VERSION ""

NS_ :

BS_:

BU_: Gateway_Front Gateway_Rear BMS_Master GI_Left GI_Right Dashboard Telemetry INS Programming Charger

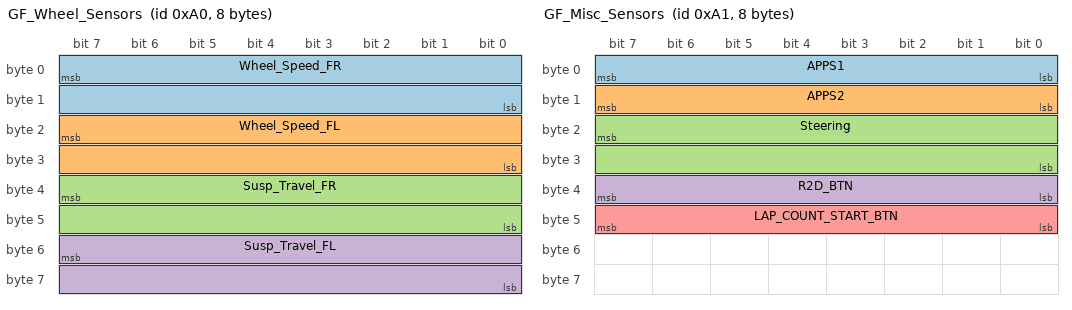
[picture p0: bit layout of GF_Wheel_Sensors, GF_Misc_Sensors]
BO_ 160 GF_Wheel_Sensors: 8 Gateway_Front
 SG_ Wheel_Speed_FR : 7|16@0+ (1.0, 0.0) [0.0|8000.0] "rpm" Telemetry,GI_Left,GI_Right,BMS_Master
 SG_ Wheel_Speed_FL : 23|16@0+ (1.0, 0.0) [0.0|8000.0] "rpm" Telemetry,GI_Left,GI_Right,BMS_Master
 SG_ Susp_Travel_FR : 39|16@0+ (0.001, 0.0) [0.0|65.535] "mm" Telemetry,GI_Left,GI_Right,BMS_Master
 SG_ Susp_Travel_FL : 55|16@0+ (0.001, 0.0) [0.0|65.535] "mm" Telemetry,GI_Left,GI_Right,BMS_Master

BO_ 161 GF_Misc_Sensors: 8 Gateway_Front
 SG_ APPS1 : 7|8@0+ (1.0, 0.0) [0.0|100.0] "%" Telemetry,GI_Left,GI_Right,BMS_Master
 SG_ APPS2 : 15|8@0+ (1.0, 0.0) [0.0|100.0] "%" Telemetry,GI_Left,GI_Right,BMS_Master
 SG_ Steering : 23|16@0- (0.01, 0.0) [-290.0|290.0] "deg" Telemetry,GI_Left,GI_Right,BMS_Master
 SG_ R2D_BTN : 39|8@0+ (1.0, 0.0) [0.0|1.0] "bool" Telemetry,GI_Left,GI_Right,BMS_Master
 SG_ LAP_COUNT_START_BTN : 47|8@0+ (1.0, 0.0) [0.0|1.0] "bool" Telemetry,GI_Left,GI_Right,BMS_Master

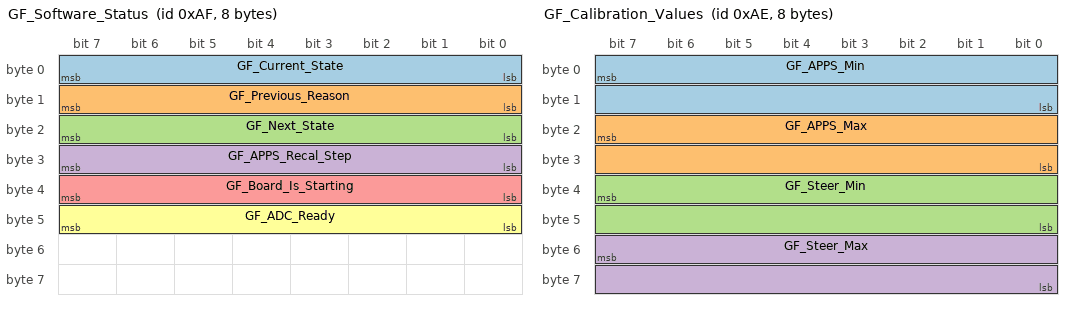
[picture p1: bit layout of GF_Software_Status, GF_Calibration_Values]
BO_ 175 GF_Software_Status: 8 Gateway_Front
 SG_ GF_Current_State : 7|8@0+ (1.0, 0.0) [0.0|255.0] "hex" Telemetry
 SG_ GF_Previous_Reason : 15|8@0+ (1.0, 0.0) [0.0|255.0] "hex" Telemetry
 SG_ GF_Next_State : 23|8@0+ (1.0, 0.0) [0.0|255.0] "hex" Telemetry
 SG_ GF_APPS_Recal_Step : 31|8@0+ (1.0, 0.0) [0.0|3.0] "hex" Telemetry
 SG_ GF_Board_Is_Starting : 39|8@0+ (1.0, 0.0) [0.0|1.0] "bool" Telemetry
 SG_ GF_ADC_Ready : 47|8@0+ (1.0, 0.0) [0.0|1.0] "bool" Telemetry

BO_ 174 GF_Calibration_Values: 8 Gateway_Front
 SG_ GF_APPS_Min : 7|16@0+ (1.0, 0.0) [0.0|65535.0] "dec" Telemetry,Dashboard
 SG_ GF_APPS_Max : 23|16@0+ (1.0, 0.0) [0.0|65535.0] "dec" Telemetry,Dashboard
 SG_ GF_Steer_Min : 39|16@0+ (1.0, 0.0) [0.0|65535.0] "dec" Telemetry,Dashboard
 SG_ GF_Steer_Max : 55|16@0+ (1.0, 0.0) [0.0|65535.0] "dec" Telemetry,Dashboard

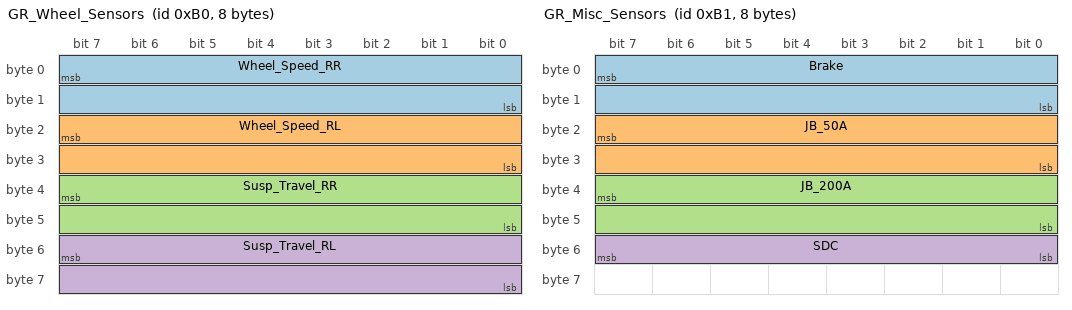
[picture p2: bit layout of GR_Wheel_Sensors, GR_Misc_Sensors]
BO_ 176 GR_Wheel_Sensors: 8 Gateway_Rear
 SG_ Wheel_Speed_RR : 7|16@0+ (1.0, 0.0) [0.0|8000.0] "rpm" Telemetry,GI_Left,GI_Right,BMS_Master
 SG_ Wheel_Speed_RL : 23|16@0+ (1.0, 0.0) [0.0|8000.0] "rpm" Telemetry,GI_Left,GI_Right,BMS_Master
 SG_ Susp_Travel_RR : 39|16@0+ (0.001, 0.0) [0.0|65.535] "mm" Telemetry,GI_Left,GI_Right,BMS_Master
 SG_ Susp_Travel_RL : 55|16@0+ (0.001, 0.0) [0.0|65.535] "mm" Telemetry,GI_Left,GI_Right,BMS_Master

BO_ 177 GR_Misc_Sensors: 8 Gateway_Rear
 SG_ Brake : 7|16@0+ (0.01, 0.0) [0.0|100.0] "bar" Telemetry,GI_Left,GI_Right,BMS_Master
 SG_ JB_50A : 23|16@0- (0.01, 0.0) [-70.0|70.0] "A" Telemetry,GI_Left,GI_Right,BMS_Master
 SG_ JB_200A : 39|16@0- (0.01, 0.0) [-300.0|300.0] "A" Telemetry,GI_Left,GI_Right,BMS_Master
 SG_ SDC : 55|8@0+ (1.0, 0.0) [0.0|1.0] "Bool" Telemetry,GI_Left,GI_Right,BMS_Master

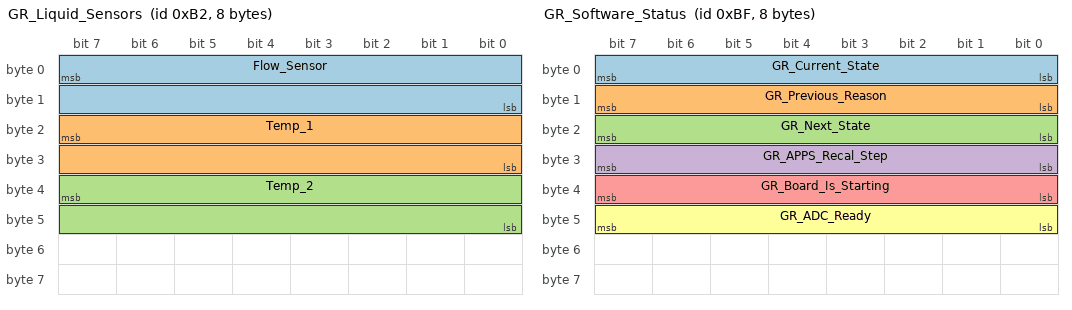
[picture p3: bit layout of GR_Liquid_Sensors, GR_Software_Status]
BO_ 178 GR_Liquid_Sensors: 8 Gateway_Rear
 SG_ Flow_Sensor : 7|16@0+ (1.0, 0.0) [0.0|100.0] "L/m" Telemetry
 SG_ Temp_1 : 23|16@0- (0.001, 0.0) [-10.0|100.0] "degC" Telemetry
 SG_ Temp_2 : 39|16@0- (0.001, 0.0) [-10.0|100.0] "degC" Telemetry

BO_ 191 GR_Software_Status: 8 Gateway_Rear
 SG_ GR_Current_State : 7|8@0+ (1.0, 0.0) [0.0|255.0] "hex" Telemetry
 SG_ GR_Previous_Reason : 15|8@0+ (1.0, 0.0) [0.0|255.0] "hex" Telemetry
 SG_ GR_Next_State : 23|8@0+ (1.0, 0.0) [0.0|255.0] "hex" Telemetry
 SG_ GR_APPS_Recal_Step : 31|8@0+ (1.0, 0.0) [0.0|3.0] "hex" Telemetry
 SG_ GR_Board_Is_Starting : 39|8@0+ (1.0, 0.0) [0.0|1.0] "bool" Telemetry
 SG_ GR_ADC_Ready : 47|8@0+ (1.0, 0.0) [0.0|1.0] "bool" Telemetry

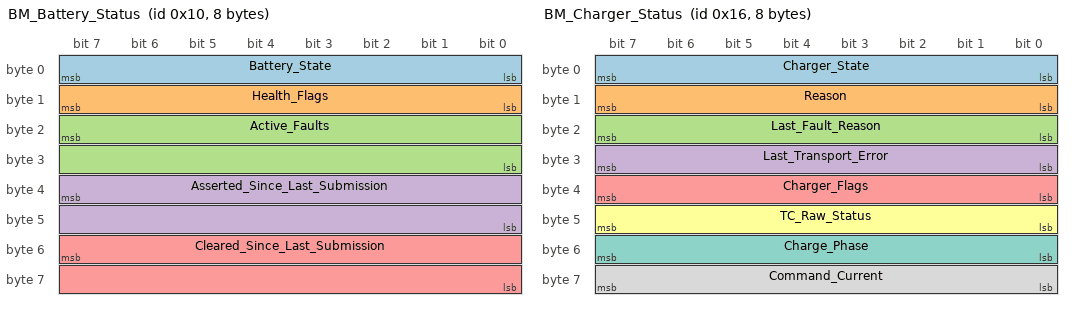
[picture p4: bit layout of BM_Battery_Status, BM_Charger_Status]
BO_ 16 BM_Battery_Status: 8 BMS_Master
 SG_ Battery_State : 7|8@0+ (1.0, 0.0) [0.0|5.0] "enum" Telemetry,Dashboard
 SG_ Health_Flags : 15|8@0+ (1.0, 0.0) [0.0|15.0] "bits" Telemetry,Dashboard
 SG_ Active_Faults : 23|16@0+ (1.0, 0.0) [0.0|32767.0] "bits" Telemetry,Dashboard
 SG_ Asserted_Since_Last_Submission : 39|16@0+ (1.0, 0.0) [0.0|32767.0] "bits" Telemetry,Dashboard
 SG_ Cleared_Since_Last_Submission : 55|16@0+ (1.0, 0.0) [0.0|32767.0] "bits" Telemetry,Dashboard

BO_ 22 BM_Charger_Status: 8 BMS_Master
 SG_ Charger_State : 7|8@0+ (1.0, 0.0) [0.0|5.0] "enum" Telemetry,Dashboard
 SG_ Reason : 15|8@0+ (1.0, 0.0) [0.0|9.0] "enum" Telemetry,Dashboard
 SG_ Last_Fault_Reason : 23|8@0+ (1.0, 0.0) [0.0|9.0] "enum" Telemetry,Dashboard
 SG_ Last_Transport_Error : 31|8@0+ (1.0, 0.0) [0.0|10.0] "enum" Telemetry,Dashboard
 SG_ Charger_Flags : 39|8@0+ (1.0, 0.0) [0.0|63.0] "bits" Telemetry,Dashboard
 SG_ TC_Raw_Status : 47|8@0+ (1.0, 0.0) [0.0|255.0] "bits" Telemetry,Dashboard
 SG_ Charge_Phase : 55|8@0+ (1.0, 0.0) [0.0|4.0] "enum" Telemetry,Dashboard
 SG_ Command_Current : 63|8@0+ (100.0, 0.0) [0.0|20000.0] "mA" Telemetry,Dashboard

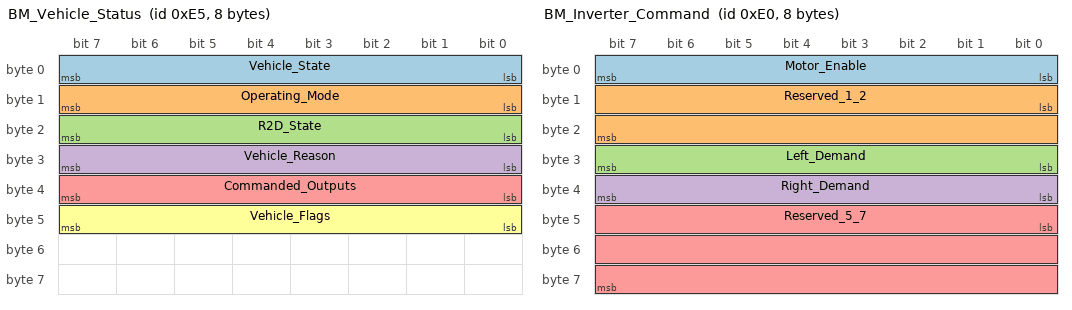
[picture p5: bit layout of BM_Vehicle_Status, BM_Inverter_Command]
BO_ 229 BM_Vehicle_Status: 8 BMS_Master
 SG_ Vehicle_State : 7|8@0+ (1.0, 0.0) [0.0|5.0] "enum" Telemetry,Dashboard
 SG_ Operating_Mode : 15|8@0+ (1.0, 0.0) [0.0|1.0] "enum" Telemetry,Dashboard
 SG_ R2D_State : 23|8@0+ (1.0, 0.0) [0.0|4.0] "enum" Telemetry,Dashboard
 SG_ Vehicle_Reason : 31|8@0+ (1.0, 0.0) [0.0|9.0] "enum" Telemetry,Dashboard
 SG_ Commanded_Outputs : 39|8@0+ (1.0, 0.0) [0.0|63.0] "bits" Telemetry,Dashboard
 SG_ Vehicle_Flags : 47|8@0+ (1.0, 0.0) [0.0|3.0] "bits" Telemetry,Dashboard

BO_ 224 BM_Inverter_Command: 8 BMS_Master
 SG_ Motor_Enable : 0|8@1+ (1.0, 0.0) [0.0|1.0] "bool" Telemetry,GI_Left,GI_Right
 SG_ Reserved_1_2 : 8|16@1+ (1.0, 0.0) [0.0|0.0] "" Telemetry,GI_Left,GI_Right
 SG_ Left_Demand : 24|8@1+ (1.0, 0.0) [0.0|100.0] "%" Telemetry,GI_Left,GI_Right
 SG_ Right_Demand : 32|8@1+ (1.0, 0.0) [0.0|100.0] "%" Telemetry,GI_Left,GI_Right
 SG_ Reserved_5_7 : 40|24@1+ (1.0, 0.0) [0.0|0.0] "" Telemetry,GI_Left,GI_Right

BO_ 179 BM_Rear_Buzzer: 8 BMS_Master
 SG_ R2D_Buzzer : 0|8@1+ (1.0, 0.0) [0.0|1.0] "bool" Telemetry,Gateway_Rear
 SG_ Reserved : 8|56@1+ (1.0, 0.0) [0.0|0.0] "" Telemetry,Gateway_Rear

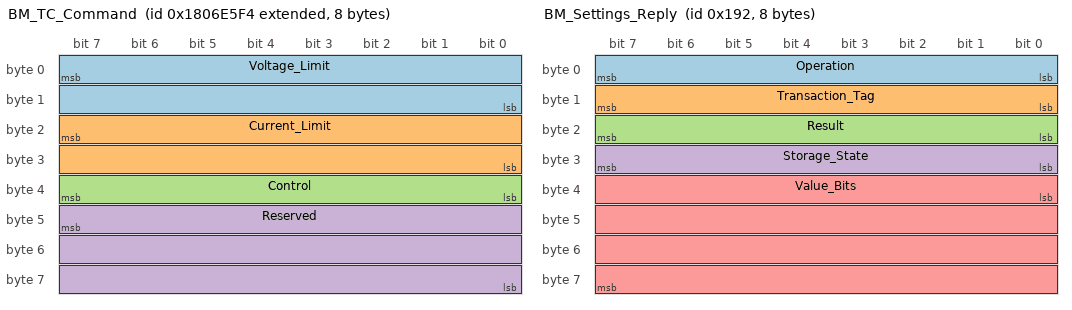
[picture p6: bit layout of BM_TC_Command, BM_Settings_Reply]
BO_ 2550588916 BM_TC_Command: 8 BMS_Master
 SG_ Voltage_Limit : 7|16@0+ (0.1, 0.0) [0.0|440.0] "V" Charger
 SG_ Current_Limit : 23|16@0+ (0.1, 0.0) [0.0|20.0] "A" Charger
 SG_ Control : 39|8@0+ (1.0, 0.0) [0.0|1.0] "enum" Charger
 SG_ Reserved : 47|24@0+ (1.0, 0.0) [0.0|0.0] "" Charger

BO_ 402 BM_Settings_Reply: 8 BMS_Master
 SG_ Operation : 0|8@1+ (1.0, 0.0) [0.0|255.0] "enum" Programming,Telemetry
 SG_ Transaction_Tag : 8|8@1+ (1.0, 0.0) [0.0|255.0] "" Programming,Telemetry
 SG_ Result : 16|8@1+ (1.0, 0.0) [0.0|10.0] "enum" Programming,Telemetry
 SG_ Storage_State : 24|8@1+ (1.0, 0.0) [0.0|3.0] "enum" Programming,Telemetry
 SG_ Value_Bits : 32|32@1+ (1.0, 0.0) [0.0|4294967295.0] "" Programming,Telemetry

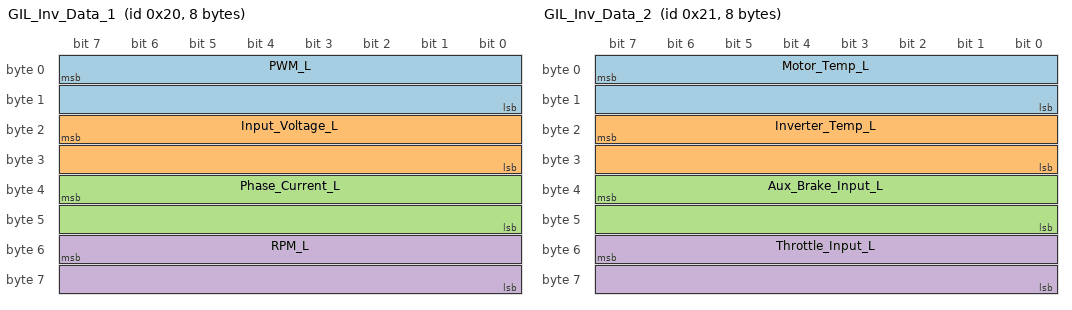
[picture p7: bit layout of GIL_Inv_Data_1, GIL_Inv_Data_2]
BO_ 32 GIL_Inv_Data_1: 8 GI_Left
 SG_ PWM_L : 7|16@0+ (1.0, 0.0) [0.0|1000.0] "raw" Telemetry
 SG_ Input_Voltage_L : 23|16@0+ (0.1, 0.0) [0.0|410.0] "V" Telemetry
 SG_ Phase_Current_L : 39|16@0+ (0.1, 0.0) [0.0|511.0] "A" Telemetry
 SG_ RPM_L : 55|16@0+ (1.0, 0.0) [0.0|65535.0] "rpm" Telemetry

BO_ 33 GIL_Inv_Data_2: 8 GI_Left
 SG_ Motor_Temp_L : 7|16@0- (1.0, 0.0) [-100.0|155.0] "degC" Telemetry
 SG_ Inverter_Temp_L : 23|16@0- (1.0, 0.0) [-100.0|155.0] "degC" Telemetry
 SG_ Aux_Brake_Input_L : 39|16@0+ (0.001, 0.0) [0.0|5.0] "V" Telemetry
 SG_ Throttle_Input_L : 55|16@0+ (0.001, 0.0) [0.0|5.0] "V" Telemetry

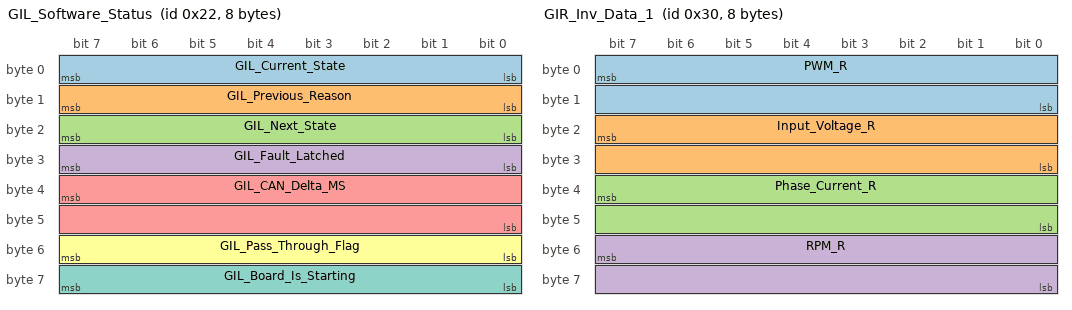
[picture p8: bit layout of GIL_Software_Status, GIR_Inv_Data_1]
BO_ 34 GIL_Software_Status: 8 GI_Left
 SG_ GIL_Current_State : 7|8@0+ (1.0, 0.0) [0.0|255.0] "hex" Telemetry
 SG_ GIL_Previous_Reason : 15|8@0+ (1.0, 0.0) [0.0|255.0] "hex" Telemetry
 SG_ GIL_Next_State : 23|8@0+ (1.0, 0.0) [0.0|255.0] "hex" Telemetry
 SG_ GIL_Fault_Latched : 31|8@0+ (1.0, 0.0) [0.0|1.0] "bool" Telemetry
 SG_ GIL_CAN_Delta_MS : 39|16@0+ (1.0, 0.0) [0.0|65535.0] "hex" Telemetry
 SG_ GIL_Pass_Through_Flag : 55|8@0+ (1.0, 0.0) [0.0|1.0] "bool" Telemetry
 SG_ GIL_Board_Is_Starting : 63|8@0+ (1.0, 0.0) [0.0|1.0] "bool" Telemetry

BO_ 48 GIR_Inv_Data_1: 8 GI_Right
 SG_ PWM_R : 7|16@0+ (1.0, 0.0) [0.0|1000.0] "raw" Telemetry
 SG_ Input_Voltage_R : 23|16@0+ (0.1, 0.0) [0.0|410.0] "V" Telemetry
 SG_ Phase_Current_R : 39|16@0+ (0.1, 0.0) [0.0|511.0] "A" Telemetry
 SG_ RPM_R : 55|16@0+ (1.0, 0.0) [0.0|65535.0] "rpm" Telemetry

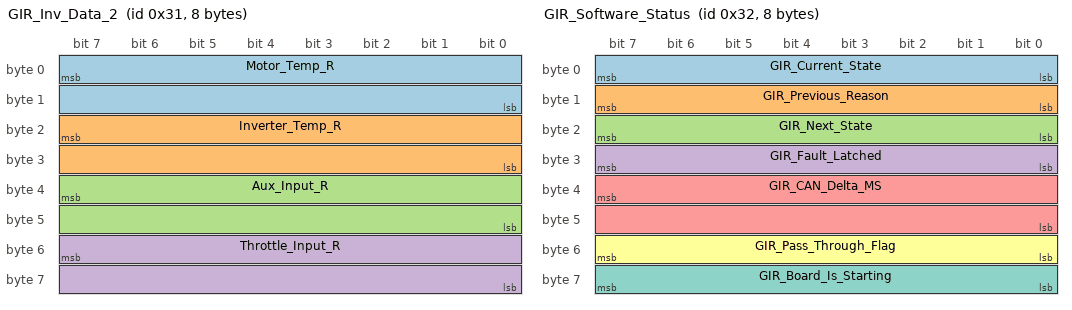
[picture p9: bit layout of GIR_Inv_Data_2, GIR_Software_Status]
BO_ 49 GIR_Inv_Data_2: 8 GI_Right
 SG_ Motor_Temp_R : 7|16@0- (1.0, 0.0) [-100.0|155.0] "degC" Telemetry
 SG_ Inverter_Temp_R : 23|16@0- (1.0, 0.0) [-100.0|155.0] "degC" Telemetry
 SG_ Aux_Input_R : 39|16@0+ (0.001, 0.0) [0.0|5.0] "V" Telemetry
 SG_ Throttle_Input_R : 55|16@0+ (0.001, 0.0) [0.0|5.0] "V" Telemetry

BO_ 50 GIR_Software_Status: 8 GI_Right
 SG_ GIR_Current_State : 7|8@0+ (1.0, 0.0) [0.0|255.0] "hex" Telemetry
 SG_ GIR_Previous_Reason : 15|8@0+ (1.0, 0.0) [0.0|255.0] "hex" Telemetry
 SG_ GIR_Next_State : 23|8@0+ (1.0, 0.0) [0.0|255.0] "hex" Telemetry
 SG_ GIR_Fault_Latched : 31|8@0+ (1.0, 0.0) [0.0|1.0] "bool" Telemetry
 SG_ GIR_CAN_Delta_MS : 39|16@0+ (1.0, 0.0) [0.0|65535.0] "hex" Telemetry
 SG_ GIR_Pass_Through_Flag : 55|8@0+ (1.0, 0.0) [0.0|1.0] "bool" Telemetry
 SG_ GIR_Board_Is_Starting : 63|8@0+ (1.0, 0.0) [0.0|1.0] "bool" Telemetry

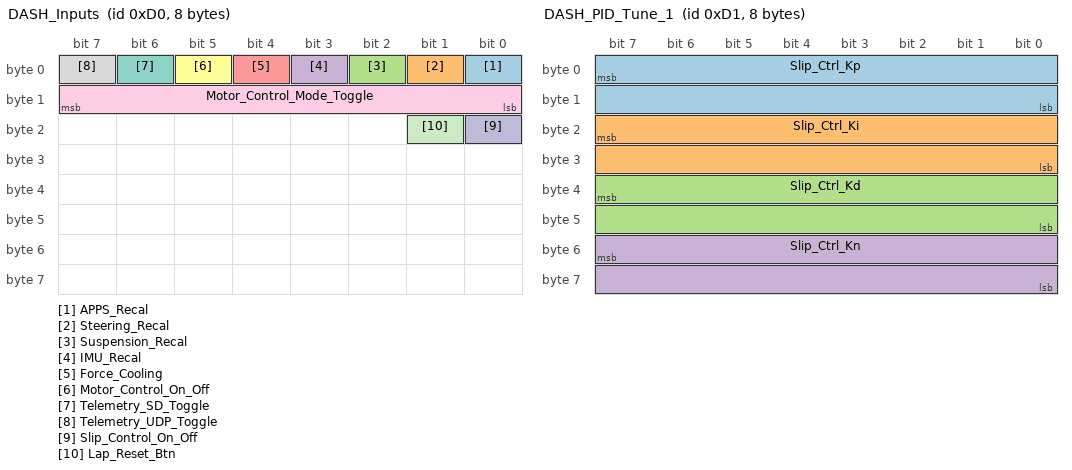
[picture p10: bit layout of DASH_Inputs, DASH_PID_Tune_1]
BO_ 208 DASH_Inputs: 8 Dashboard
 SG_ APPS_Recal : 0|1@1+ (1.0, 0.0) [0.0|1.0] "bool" Telemetry,BMS_Master
 SG_ Steering_Recal : 1|1@1+ (1.0, 0.0) [0.0|1.0] "bool" Telemetry,BMS_Master
 SG_ Suspension_Recal : 2|1@1+ (1.0, 0.0) [0.0|1.0] "bool" Telemetry,BMS_Master
 SG_ IMU_Recal : 3|1@1+ (1.0, 0.0) [0.0|1.0] "bool" Telemetry,BMS_Master
 SG_ Force_Cooling : 4|1@1+ (1.0, 0.0) [0.0|1.0] "bool" Telemetry,BMS_Master
 SG_ Motor_Control_On_Off : 5|1@1+ (1.0, 0.0) [0.0|1.0] "enum" Telemetry,BMS_Master
 SG_ Telemetry_SD_Toggle : 6|1@1+ (1.0, 0.0) [0.0|1.0] "bool" Telemetry,BMS_Master
 SG_ Telemetry_UDP_Toggle : 7|1@1+ (1.0, 0.0) [0.0|1.0] "bool" Telemetry,BMS_Master
 SG_ Motor_Control_Mode_Toggle : 15|8@0+ (1.0, 0.0) [0.0|255.0] "enum" Telemetry,BMS_Master
 SG_ Slip_Control_On_Off : 16|1@1+ (1.0, 0.0) [0.0|1.0] "bool" Telemetry,BMS_Master
 SG_ Lap_Reset_Btn : 17|1@1+ (1.0, 0.0) [0.0|1.0] "bool" Telemetry,BMS_Master

BO_ 209 DASH_PID_Tune_1: 8 Dashboard
 SG_ Slip_Ctrl_Kp : 7|16@0+ (1.0, 0.0) [0.0|65535.0] "unit" Telemetry
 SG_ Slip_Ctrl_Ki : 23|16@0+ (1.0, 0.0) [0.0|65535.0] "unit" Telemetry
 SG_ Slip_Ctrl_Kd : 39|16@0+ (0.01, 0.0) [0.0|655.35] "unit" Telemetry
 SG_ Slip_Ctrl_Kn : 55|16@0+ (1.0, 0.0) [0.0|100.0] "unit" Telemetry

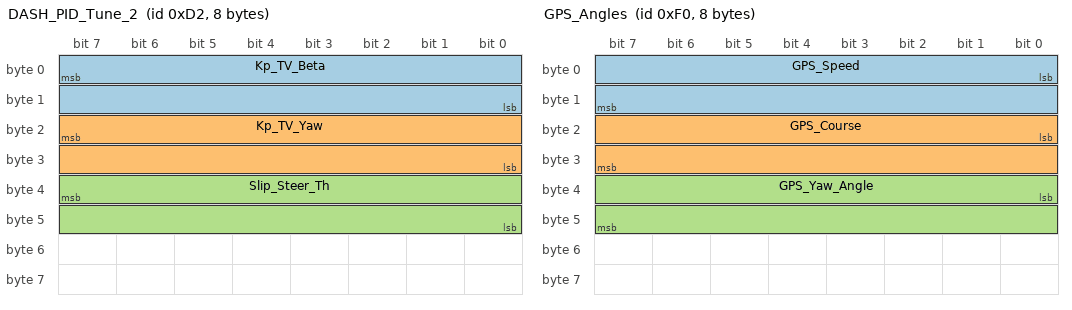
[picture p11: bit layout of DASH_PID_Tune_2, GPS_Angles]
BO_ 210 DASH_PID_Tune_2: 8 Dashboard
 SG_ Kp_TV_Beta : 7|16@0+ (1.0, 0.0) [0.0|1000.0] "unit" Telemetry
 SG_ Kp_TV_Yaw : 23|16@0+ (1.0, 0.0) [0.0|1500.0] "unit" Telemetry
 SG_ Slip_Steer_Th : 39|16@0+ (1.0, 0.0) [0.0|255.0] "deg" Telemetry

BO_ 240 GPS_Angles: 8 Telemetry
 SG_ GPS_Speed : 0|16@1- (0.01, 0.0) [0.0|327.67] "m/s" BMS_Master
 SG_ GPS_Course : 16|16@1- (0.0001, 0.0) [-3.15|3.15] "rad" BMS_Master
 SG_ GPS_Yaw_Angle : 32|16@1- (0.0001, 0.0) [-3.15|3.15] "rad" BMS_Master

BO_ 241 Lap_Completed: 8 Telemetry
 SG_ Lap_Completed_Flag : 7|8@0+ (1.0, 0.0) [0.0|1.0] "bool" Dashboard
 SG_ Lap_Count : 15|16@0+ (1.0, 0.0) [0.0|65535.0] "dec" Dashboard

BO_ 258 SBG_ECAN_MSG_STATUS_03: 6 INS
 SG_ SOLUTION : 0|32@1+ (1.0, 0.0) [0.0|4294967295.0] "" Telemetry
 SG_ HEAVE_STATUS : 32|16@1+ (1.0, 0.0) [0.0|65535.0] "" Telemetry

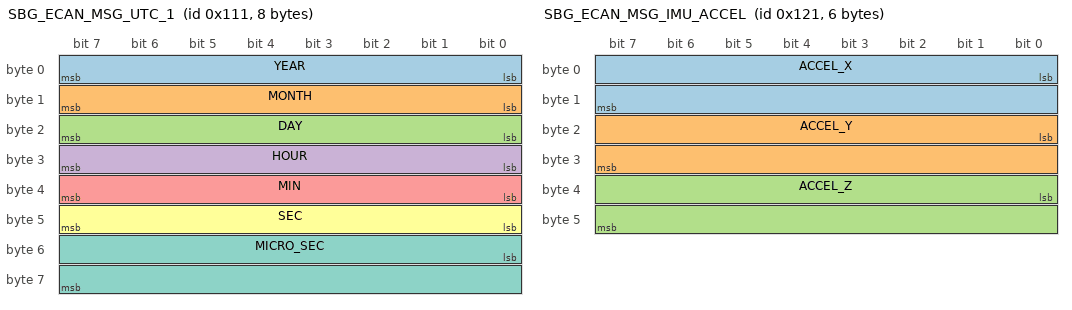
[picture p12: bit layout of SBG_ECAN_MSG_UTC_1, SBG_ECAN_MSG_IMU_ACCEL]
BO_ 273 SBG_ECAN_MSG_UTC_1: 8 INS
 SG_ YEAR : 0|8@1+ (1.0, 2000.0) [2000.0|2255.0] "year" Telemetry
 SG_ MONTH : 8|8@1+ (1.0, 0.0) [0.0|255.0] "month" Telemetry
 SG_ DAY : 16|8@1+ (1.0, 0.0) [0.0|255.0] "d" Telemetry
 SG_ HOUR : 24|8@1+ (1.0, 0.0) [0.0|255.0] "h" Telemetry
 SG_ MIN : 32|8@1+ (1.0, 0.0) [0.0|255.0] "min" Telemetry
 SG_ SEC : 40|8@1+ (1.0, 0.0) [0.0|255.0] "s" Telemetry
 SG_ MICRO_SEC : 48|16@1+ (100.0, 0.0) [0.0|6553500.0] "us" Telemetry

BO_ 289 SBG_ECAN_MSG_IMU_ACCEL: 6 INS
 SG_ ACCEL_X : 0|16@1- (0.01, 0.0) [-327.68|327.67] "m.s-2" BMS_Master,Telemetry
 SG_ ACCEL_Y : 16|16@1- (0.01, 0.0) [-327.68|327.67] "m.s-2" BMS_Master,Telemetry
 SG_ ACCEL_Z : 32|16@1- (0.01, 0.0) [-327.68|327.67] "m.s-2" BMS_Master,Telemetry

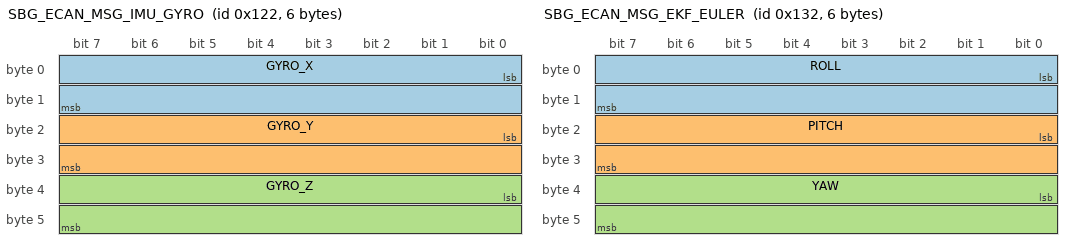
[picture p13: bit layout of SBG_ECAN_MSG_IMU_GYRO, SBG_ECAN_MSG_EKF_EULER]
BO_ 290 SBG_ECAN_MSG_IMU_GYRO: 6 INS
 SG_ GYRO_X : 0|16@1- (0.001, 0.0) [-32.768|32.767] "rad.s-1" BMS_Master,Telemetry
 SG_ GYRO_Y : 16|16@1- (0.001, 0.0) [-32.768|32.767] "rad.s-1" BMS_Master,Telemetry
 SG_ GYRO_Z : 32|16@1- (0.001, 0.0) [-32.768|32.767] "rad.s-1" BMS_Master,Telemetry

BO_ 306 SBG_ECAN_MSG_EKF_EULER: 6 INS
 SG_ ROLL : 0|16@1- (0.0001, 0.0) [-3.2768|3.2767] "rad" Telemetry
 SG_ PITCH : 16|16@1- (0.0001, 0.0) [-3.2768|3.2767] "rad" Telemetry
 SG_ YAW : 32|16@1- (0.0001, 0.0) [-3.2768|3.2767] "rad" Telemetry

BO_ 308 SBG_ECAN_MSG_EKF_POS: 8 INS
 SG_ LATITUDE : 0|32@1- (1e-07, 0.0) [-214.7483648|214.7483647] "Â°" Telemetry
 SG_ LONGITUDE : 32|32@1- (1e-07, 0.0) [-214.7483648|214.7483647] "Â°" Telemetry

BO_ 309 SBG_ECAN_MSG_EKF_ALTITUDE: 6 INS
 SG_ ALTITUDE : 0|32@1- (0.001, 0.0) [-2147480.0|2147480.0] "m" Telemetry
 SG_ UNDULATION : 32|16@1- (0.005, 0.0) [-163.84|163.835] "m" Telemetry

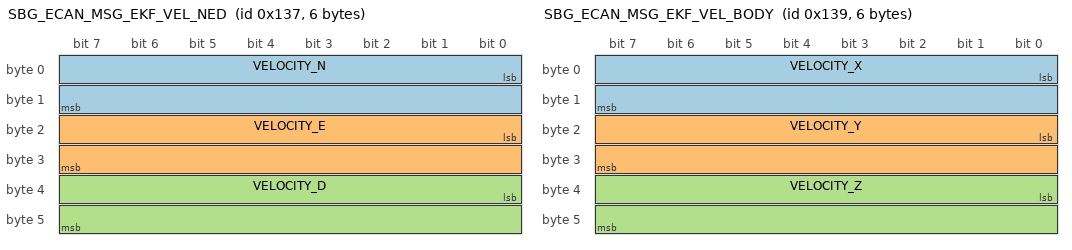
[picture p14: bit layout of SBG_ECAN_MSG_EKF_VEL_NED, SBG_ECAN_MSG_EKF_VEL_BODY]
BO_ 311 SBG_ECAN_MSG_EKF_VEL_NED: 6 INS
 SG_ VELOCITY_N : 0|16@1- (0.01, 0.0) [-327.68|327.67] "m.s-1" Telemetry
 SG_ VELOCITY_E : 16|16@1- (0.01, 0.0) [-327.68|327.67] "m.s-1" Telemetry
 SG_ VELOCITY_D : 32|16@1- (0.01, 0.0) [-327.68|327.67] "m.s-1" Telemetry

BO_ 313 SBG_ECAN_MSG_EKF_VEL_BODY: 6 INS
 SG_ VELOCITY_X : 0|16@1- (0.01, 0.0) [-327.68|327.67] "m.s-1" Telemetry
 SG_ VELOCITY_Y : 16|16@1- (0.01, 0.0) [-327.68|327.67] "m.s-1" Telemetry
 SG_ VELOCITY_Z : 32|16@1- (0.01, 0.0) [-327.68|327.67] "m.s-1" Telemetry

BO_ 372 SBG_ECAN_MSG_GPS1_POS_INFO: 8 INS
 SG_ TIME_STAMP : 0|32@1+ (1.0, 0.0) [0.0|4294967295.0] "Âµs" Telemetry
 SG_ STATUS : 32|32@1+ (1.0, 0.0) [0.0|4294967295.0] "" Telemetry

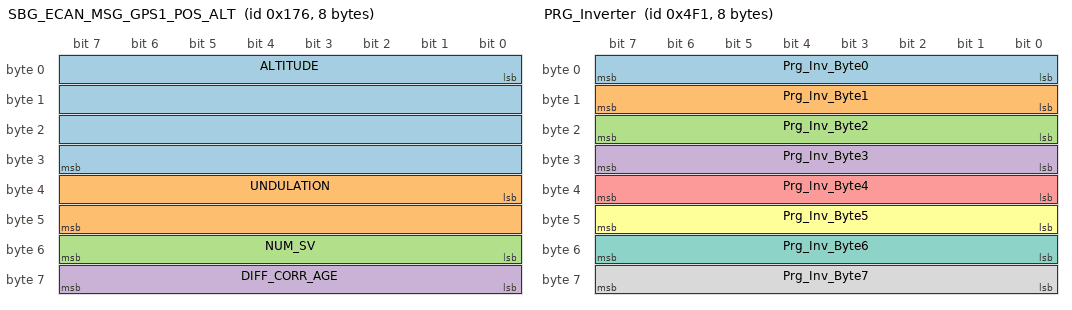
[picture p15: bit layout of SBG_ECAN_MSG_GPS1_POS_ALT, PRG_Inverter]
BO_ 374 SBG_ECAN_MSG_GPS1_POS_ALT: 8 INS
 SG_ ALTITUDE : 0|32@1- (0.001, 0.0) [-2147480.0|2147480.0] "m" Telemetry
 SG_ UNDULATION : 32|16@1- (0.005, 0.0) [-163.84|163.835] "m" Telemetry
 SG_ NUM_SV : 48|8@1+ (1.0, 0.0) [0.0|255.0] "" Telemetry
 SG_ DIFF_CORR_AGE : 56|8@1+ (1.0, 0.0) [0.0|255.0] "s" Telemetry

BO_ 1264 PRG_Bootloader: 8 Programming
 SG_ MCU_ID : 7|8@0+ (1.0, 0.0) [0.0|255.0] "id" Gateway_Front,Gateway_Rear,GI_Left,GI_Right,Dashboard,Telemetry

BO_ 1265 PRG_Inverter: 8 Programming
 SG_ Prg_Inv_Byte0 : 7|8@0+ (1.0, 0.0) [0.0|255.0] "hex" GI_Left,GI_Right
 SG_ Prg_Inv_Byte1 : 15|8@0+ (1.0, 0.0) [0.0|255.0] "hex" GI_Left,GI_Right
 SG_ Prg_Inv_Byte2 : 23|8@0+ (1.0, 0.0) [0.0|255.0] "hex" GI_Left,GI_Right
 SG_ Prg_Inv_Byte3 : 31|8@0+ (1.0, 0.0) [0.0|255.0] "hex" GI_Left,GI_Right
 SG_ Prg_Inv_Byte4 : 39|8@0+ (1.0, 0.0) [0.0|255.0] "hex" GI_Left,GI_Right
 SG_ Prg_Inv_Byte5 : 47|8@0+ (1.0, 0.0) [0.0|255.0] "hex" GI_Left,GI_Right
 SG_ Prg_Inv_Byte6 : 55|8@0+ (1.0, 0.0) [0.0|255.0] "hex" GI_Left,GI_Right
 SG_ Prg_Inv_Byte7 : 63|8@0+ (1.0, 0.0) [0.0|255.0] "hex" GI_Left,GI_Right

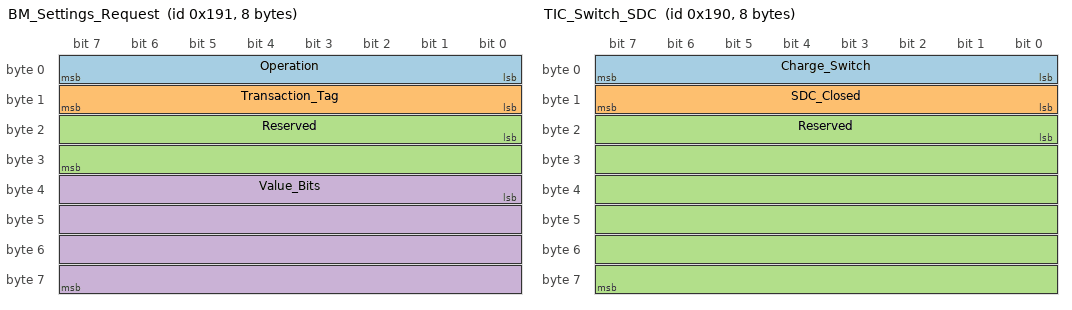
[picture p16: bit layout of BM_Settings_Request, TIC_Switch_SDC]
BO_ 401 BM_Settings_Request: 8 Programming
 SG_ Operation : 0|8@1+ (1.0, 0.0) [0.0|255.0] "enum" BMS_Master
 SG_ Transaction_Tag : 8|8@1+ (1.0, 0.0) [0.0|255.0] "" BMS_Master
 SG_ Reserved : 16|16@1+ (1.0, 0.0) [0.0|0.0] "" BMS_Master
 SG_ Value_Bits : 32|32@1+ (1.0, 0.0) [0.0|4294967295.0] "" BMS_Master

BO_ 400 TIC_Switch_SDC: 8 Charger
 SG_ Charge_Switch : 0|8@1+ (1.0, 0.0) [0.0|1.0] "bool" BMS_Master
 SG_ SDC_Closed : 8|8@1+ (1.0, 0.0) [0.0|1.0] "bool" BMS_Master
 SG_ Reserved : 16|48@1+ (1.0, 0.0) [0.0|0.0] "" BMS_Master

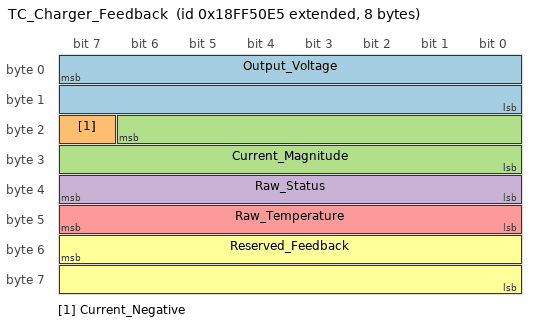
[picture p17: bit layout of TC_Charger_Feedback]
BO_ 2566869221 TC_Charger_Feedback: 8 Charger
 SG_ Output_Voltage : 7|16@0+ (0.1, 0.0) [0.0|6553.5] "V" BMS_Master
 SG_ Current_Negative : 23|1@0+ (1.0, 0.0) [0.0|1.0] "bool" BMS_Master
 SG_ Current_Magnitude : 22|15@0+ (0.1, 0.0) [0.0|3276.7] "A" BMS_Master
 SG_ Raw_Status : 39|8@0+ (1.0, 0.0) [0.0|255.0] "bits" BMS_Master
 SG_ Raw_Temperature : 47|8@0+ (1.0, 0.0) [0.0|255.0] "raw" BMS_Master
 SG_ Reserved_Feedback : 55|16@0+ (1.0, 0.0) [0.0|65535.0] "raw" BMS_Master

BA_DEF_ BO_ "GenMsgCycleTime" INT 0 65535;
BA_DEF_DEF_ "GenMsgCycleTime" 0;
BA_ "GenMsgCycleTime" BO_ 160 7;
BA_ "GenMsgCycleTime" BO_ 161 7;
BA_ "GenMsgCycleTime" BO_ 176 7;
BA_ "GenMsgCycleTime" BO_ 177 7;
BA_ "GenMsgCycleTime" BO_ 178 200;
BA_ "GenMsgCycleTime" BO_ 224 10;
BA_ "GenMsgCycleTime" BO_ 179 10;
BA_ "GenMsgCycleTime" BO_ 32 20;
BA_ "GenMsgCycleTime" BO_ 33 20;
BA_ "GenMsgCycleTime" BO_ 48 20;
BA_ "GenMsgCycleTime" BO_ 49 20;
BA_ "GenMsgCycleTime" BO_ 240 50;
BA_ "GenMsgCycleTime" BO_ 258 200;
BA_ "GenMsgCycleTime" BO_ 273 1000;
BA_ "GenMsgCycleTime" BO_ 289 20;
BA_ "GenMsgCycleTime" BO_ 290 20;
BA_ "GenMsgCycleTime" BO_ 306 20;
BA_ "GenMsgCycleTime" BO_ 308 20;
BA_ "GenMsgCycleTime" BO_ 309 200;
BA_ "GenMsgCycleTime" BO_ 311 20;
BA_ "GenMsgCycleTime" BO_ 313 20;
BA_ "GenMsgCycleTime" BO_ 372 200;
BA_ "GenMsgCycleTime" BO_ 374 200;
BA_ "GenMsgCycleTime" BO_ 400 100;
VAL_ 175 GF_Current_State 0 "BOARD_FSM_MODE_INIT" 1 "BOARD_FSM_MODE_IDLE" 2 "BOARD_FSM_MODE_PROCESS_SENSORS" 3 "BOARD_FSM_MODE_OUTPUT_SENSORS" 4 "BOARD_FSM_MODE_BOOTLOADER" 5 "BOARD_FSM_MODE_FAULT" ;
VAL_ 175 GF_Previous_Reason 0 "BOARD_FSM_REASON_NONE" 1 "BOARD_FSM_REASON_INIT_COMPLETE" 2 "BOARD_FSM_REASON_ADC_READY" 3 "BOARD_FSM_REASON_PROCESS_SENSORS_DONE" 4 "BOARD_FSM_REASON_OUTPUT_SENSORS_COMPLETE" 5 "BOARD_FSM_REASON_BOOTLOADER_REQUEST" 6 "BOARD_FSM_REASON_FORCE_FAULT" 7 "BOARD_FSM_REASON_INVALID_EVENT" ;
VAL_ 175 GF_Next_State 0 "BOARD_FSM_MODE_INIT" 1 "BOARD_FSM_MODE_IDLE" 2 "BOARD_FSM_MODE_PROCESS_SENSORS" 3 "BOARD_FSM_MODE_OUTPUT_SENSORS" 4 "BOARD_FSM_MODE_BOOTLOADER" 5 "BOARD_FSM_MODE_FAULT" ;
VAL_ 191 GR_Current_State 0 "BOARD_FSM_MODE_INIT" 1 "BOARD_FSM_MODE_IDLE" 2 "BOARD_FSM_MODE_PROCESS_SENSORS" 3 "BOARD_FSM_MODE_OUTPUT_SENSORS" 4 "BOARD_FSM_MODE_BOOTLOADER" 5 "BOARD_FSM_MODE_FAULT" ;
VAL_ 191 GR_Previous_Reason 0 "BOARD_FSM_REASON_NONE" 1 "BOARD_FSM_REASON_INIT_COMPLETE" 2 "BOARD_FSM_REASON_ADC_READY" 3 "BOARD_FSM_REASON_PROCESS_SENSORS_DONE" 4 "BOARD_FSM_REASON_OUTPUT_SENSORS_COMPLETE" 5 "BOARD_FSM_REASON_BOOTLOADER_REQUEST" 6 "BOARD_FSM_REASON_FORCE_FAULT" 7 "BOARD_FSM_REASON_INVALID_EVENT" ;
VAL_ 191 GR_Next_State 0 "BOARD_FSM_MODE_INIT" 1 "BOARD_FSM_MODE_IDLE" 2 "BOARD_FSM_MODE_PROCESS_SENSORS" 3 "BOARD_FSM_MODE_OUTPUT_SENSORS" 4 "BOARD_FSM_MODE_BOOTLOADER" 5 "BOARD_FSM_MODE_FAULT" ;
VAL_ 16 Battery_State 0 "WAITING_FOR_PORT" 1 "STOPPED" 2 "ERROR" 3 "STARTING" 4 "WAITING_FOR_DATA" 5 "MONITORING" ;
VAL_ 22 Charger_State 0 "DISABLED" 1 "READY" 2 "STARTING" 3 "ACTIVE" 4 "FAULT" 5 "COMPLETE" ;
VAL_ 22 Charge_Phase 0 "IDLE" 1 "BULK" 2 "TAPER" 3 "VOLTAGE_HOLD" 4 "COMPLETE" ;
VAL_ 229 Vehicle_State 0 "INIT" 1 "IDLE" 2 "R2D" 3 "DRIVE" 4 "SHUTDOWN" 5 "CHARGING" ;
VAL_ 229 Operating_Mode 0 "VEHICLE" 1 "STATION" ;
VAL_ 229 R2D_State 0 "FIRST_BUTTON" 1 "PRECHARGE" 2 "SECOND_BUTTON" 3 "BUZZING" 4 "R2D_IDLE" ;
VAL_ 2550588916 Control 0 "ENABLE" 1 "STOP" ;
VAL_ 402 Result 0 "OK" 1 "PARAM" 2 "NOT_INITIALIZED" 3 "BUSY" 4 "QUEUE_FULL" 5 "DUPLICATE_ID" 6 "FEATURE_DISABLED" 7 "CANCELLED" 8 "RTOS" 9 "IO" 10 "INTERLOCKED" ;
VAL_ 402 Storage_State 0 "UNSET" 1 "SAVED" 2 "PENDING" 3 "NOT_CONFIRMED_SAVED" ;
VAL_ 34 GIL_Current_State 0 "BOARD_FSM_MODE_INIT" 1 "BOARD_FSM_MODE_READY" 2 "BOARD_FSM_MODE_TORQUE_ACTIVE" 3 "BOARD_FSM_MODE_REGEN_ACTIVE" 4 "BOARD_FSM_MODE_PROGRAMMING" 5 "BOARD_FSM_MODE_BOOTLOADER" 6 "BOARD_FSM_MODE_FAULT" ;
VAL_ 34 GIL_Previous_Reason 0 "BOARD_FSM_REASON_NONE" 1 "BOARD_FSM_REASON_INIT_COMPLETE" 2 "BOARD_FSM_REASON_ECU_DISABLE" 3 "BOARD_FSM_REASON_ECU_ENABLE" 4 "BOARD_FSM_REASON_ECU_REGEN" 5 "BOARD_FSM_REASON_PASS_THROUGH" 6 "BOARD_FSM_REASON_CAN_TIMEOUT" 7 "BOARD_FSM_REASON_INVALID_CMD" 8 "BOARD_FSM_REASON_BOOTLOADER_REQUEST" ;
VAL_ 34 GIL_Next_State 0 "BOARD_FSM_MODE_INIT" 1 "BOARD_FSM_MODE_READY" 2 "BOARD_FSM_MODE_TORQUE_ACTIVE" 3 "BOARD_FSM_MODE_REGEN_ACTIVE" 4 "BOARD_FSM_MODE_PROGRAMMING" 5 "BOARD_FSM_MODE_BOOTLOADER" 6 "BOARD_FSM_MODE_FAULT" ;
VAL_ 50 GIR_Current_State 0 "BOARD_FSM_MODE_INIT" 1 "BOARD_FSM_MODE_READY" 2 "BOARD_FSM_MODE_TORQUE_ACTIVE" 3 "BOARD_FSM_MODE_REGEN_ACTIVE" 4 "BOARD_FSM_MODE_PROGRAMMING" 5 "BOARD_FSM_MODE_BOOTLOADER" 6 "BOARD_FSM_MODE_FAULT" ;
VAL_ 50 GIR_Previous_Reason 0 "BOARD_FSM_REASON_NONE" 1 "BOARD_FSM_REASON_INIT_COMPLETE" 2 "BOARD_FSM_REASON_ECU_DISABLE" 3 "BOARD_FSM_REASON_ECU_ENABLE" 4 "BOARD_FSM_REASON_ECU_REGEN" 5 "BOARD_FSM_REASON_PASS_THROUGH" 6 "BOARD_FSM_REASON_CAN_TIMEOUT" 7 "BOARD_FSM_REASON_INVALID_CMD" 8 "BOARD_FSM_REASON_BOOTLOADER_REQUEST" ;
VAL_ 50 GIR_Next_State 0 "BOARD_FSM_MODE_INIT" 1 "BOARD_FSM_MODE_READY" 2 "BOARD_FSM_MODE_TORQUE_ACTIVE" 3 "BOARD_FSM_MODE_REGEN_ACTIVE" 4 "BOARD_FSM_MODE_PROGRAMMING" 5 "BOARD_FSM_MODE_BOOTLOADER" 6 "BOARD_FSM_MODE_FAULT" ;
VAL_ 208 Motor_Control_On_Off 0 "OFF" 1 "ON" ;
VAL_ 208 Telemetry_SD_Toggle 0 "OFF" 1 "ON" ;
VAL_ 208 Telemetry_UDP_Toggle 0 "OFF" 1 "ON" ;
VAL_ 208 Slip_Control_On_Off 0 "OFF" 1 "ON" ;
VAL_ 400 Charge_Switch 0 "OFF" 1 "ON" ;
VAL_ 400 SDC_Closed 0 "OPEN" 1 "CLOSED" ;
VAL_ 2566869221 Current_Negative 0 "POSITIVE" 1 "NEGATIVE" ;
